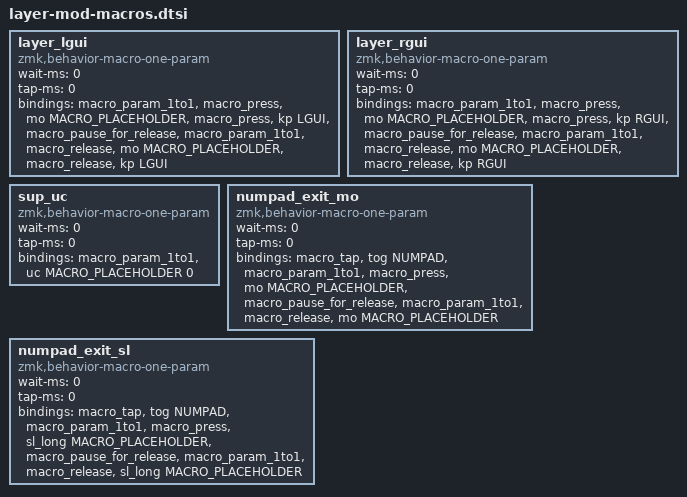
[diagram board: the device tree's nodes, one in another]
// tap once is a one shot from the layer.
// tap twice switches to it.

#define ONESHOT_OR_TO(layer) \
    oneshot_or_to_##layer: oneshot_or_to_##layer { \
        compatible = "zmk,behavior-tap-dance"; \
        #binding-cells = <0>; \
        tapping-term-ms = <TAP_DANCE_TAPPING>; \
        bindings = <&sl layer>, <&tog layer>; \
    };

ONESHOT_OR_TO(NUMERIC)
ONESHOT_OR_TO(NAVIGATION)
ONESHOT_OR_TO(FN)



// Layer + modifier hold macros. Only the GUI pair is bound -- by
// tap_hold_layer_lgui/rgui, for the pinky nav layers.






/*
 * layer_lgui: Activates a layer and holds LGUI modifier simultaneously
 * 
 * This macro activates a momentary layer while holding the LGUI (Left GUI/Windows/Command) modifier.
 * When the key is released, both the layer and modifier are released.
 * 
 * The double release of LGUI is intentional to prevent stuck modifier issues.
 */
layer_lgui: layer_lgui {
    compatible = "zmk,behavior-macro-one-param";
    wait-ms = <0>;
    tap-ms = <0>;
    #binding-cells = <1>;
    bindings
        = <&macro_param_1to1>
        , <&macro_press &mo MACRO_PLACEHOLDER>
        , <&macro_press &kp LGUI>
        , <&macro_pause_for_release>
        , <&macro_param_1to1>
        , <&macro_release &mo MACRO_PLACEHOLDER>
        , <&macro_release &kp LGUI>
        ;
};

layer_rgui: layer_rgui {
    compatible = "zmk,behavior-macro-one-param";
    wait-ms = <0>;
    tap-ms = <0>;
    #binding-cells = <1>;
    bindings
        = <&macro_param_1to1>
        , <&macro_press &mo MACRO_PLACEHOLDER>
        , <&macro_press &kp RGUI>
        , <&macro_pause_for_release>
        , <&macro_param_1to1>
        , <&macro_release &mo MACRO_PLACEHOLDER>
        , <&macro_release &kp RGUI>
        ;
};


// Unicode codepoint as a single-parameter behaviour, so it can serve as the tap
// half of a hold-tap. &uc itself takes two cells, which a hold-tap cannot feed:
// a hold-tap passes exactly one parameter to each of its two bindings. Used by
// hml_sup/hmr_sup to keep home-row mods alive on the SUPERSCRIPT layer.
sup_uc: sup_uc {
    compatible = "zmk,behavior-macro-one-param";
    #binding-cells = <1>;
    wait-ms = <0>;
    tap-ms = <0>;
    bindings
        = <&macro_param_1to1>
        , <&uc MACRO_PLACEHOLDER 0>;
};


// Leaving NUMPAD on the way into another layer.
//
// SYMBOL (7), EXTRA (11) and FN (12) all sit above NUMPAD (6), so simply
// stacking one on top would resolve its *own* keys correctly -- but every
// &trans on it would fall through to NUMPAD's digits rather than hierophant's
// letters, and EXTRA is very nearly all &trans. So the layer key drops NUMPAD
// before raising the layer it wants, which is also what jjb asked for: using
// one of these ends numpad word mode and reverts to hierophant.
//
// &tog is unconditional rather than a guess about how NUMPAD was reached.
// These bindings are only reachable FROM the NUMPAD layer, so NUMPAD is active
// by definition and &tog can only turn it off -- true whether word mode armed
// it or a held W/Q did. (&numpad_word NUMPAD would clear the auto-layer's own
// bookkeeping too, but it would ARM word mode in the held-W case, which strands
// you on a sticky NUMPAD. A stuck layer is far worse than the cost below.)
//
// The cost: the auto-layer's internal is_active flag stays set, because we went
// around it. It self-heals on the next keycode that is not in its continue-list
// (the listener clears it there). Until then, one press of the numpad-word key
// is swallowed toggling that stale flag off. Only reachable by arming a layer
// here, using nothing, and immediately re-entering word mode.
numpad_exit_mo: numpad_exit_mo {
    compatible = "zmk,behavior-macro-one-param";
    wait-ms = <0>;
    tap-ms = <0>;
    #binding-cells = <1>;
    bindings
        = <&macro_tap &tog NUMPAD>
        , <&macro_param_1to1>
        , <&macro_press &mo MACRO_PLACEHOLDER>
        , <&macro_pause_for_release>
        , <&macro_param_1to1>
        , <&macro_release &mo MACRO_PLACEHOLDER>
        ;
};

// Sticky variant, for EXTRA and FUNCTION: armed rather than held, matching how
// hierophant reaches those two (tll_sticky / tlr_sticky).
numpad_exit_sl: numpad_exit_sl {
    compatible = "zmk,behavior-macro-one-param";
    wait-ms = <0>;
    tap-ms = <0>;
    #binding-cells = <1>;
    bindings
        = <&macro_tap &tog NUMPAD>
        , <&macro_param_1to1>
        , <&macro_press &sl_long MACRO_PLACEHOLDER>
        , <&macro_pause_for_release>
        , <&macro_param_1to1>
        , <&macro_release &sl_long MACRO_PLACEHOLDER>
        ;
};
